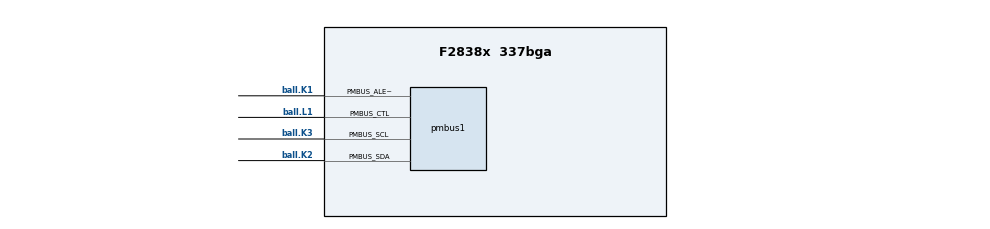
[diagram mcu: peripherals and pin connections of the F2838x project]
/**
 * @cliArgs --device "F2838x" --package "337bga" --part "F2838x_337bga" --product "C2000WARE@3.01.00.00"
 * @versions {"tool":"1.10.0+2163"}
 */

/**
 * Import the modules used in this configuration.
 */
const pmbus  = scripting.addModule("/driverlib/pmbus.js", {}, false);
const pmbus1 = pmbus.addInstance();

/**
 * Write custom configuration values to the imported modules.
 */
pmbus1.$name                        = "myPMBUS0";
pmbus1.BaudRate                     = 20000000;
pmbus1.enablePMBus                  = true;
pmbus1.registerInterrupts           = true;
pmbus1.useInterrupts                = true;
pmbus1.enabledInterrupts            = ["PMBUS_INT_ALERT","PMBUS_INT_DATA_READY","PMBUS_INT_DATA_REQUEST","PMBUS_INT_EOM"];
pmbus1.pmbus.$assign                = "PMBUSA";
pmbus1.pmbus.pmbus_alertPin.$assign = "ball.K1";
pmbus1.pmbus.pmbus_ctlPin.$assign   = "ball.L1";
pmbus1.pmbus.pmbus_sclPin.$assign   = "ball.K3";
pmbus1.pmbus.pmbus_sdaPin.$assign   = "ball.K2";
pmbus1.PMBusInt.enableInterrupt     = true;
pmbus1.PMBusInt.interruptHandler    = "pmbusIntHandler";
